# cslr_edmatc1_001 register map
Vendor: Texas Instruments
Peripheral module from a debugger description file.
Registers are 32-bit, read-only, reset 0x0 unless marked. A register's access mark holds for its fields unless they carry their own. Offsets are as the file gives them; lines under a group give offsets from that group; [hi:lo] are bit positions; {n}, {i} and the like mark numbered series; 'fields as' and 'values as' point back to an identical list; <NAME> marks a mode.

## EDMATC1 — Enhanced DMA Transfer Controller.
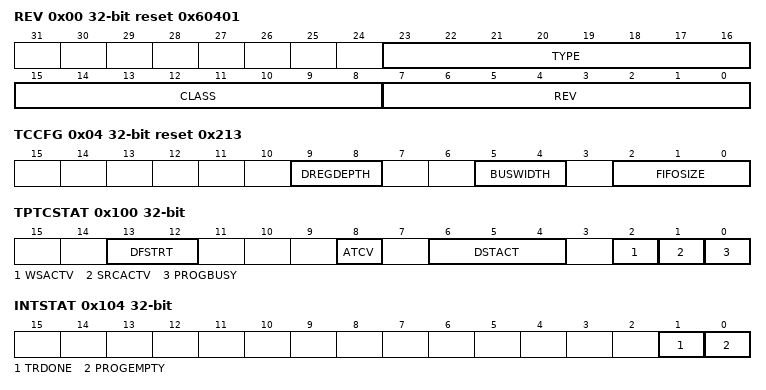
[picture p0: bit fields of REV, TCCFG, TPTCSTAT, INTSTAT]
0x00 REV reset 0x60401 — Peripheral Revision
  [23:16] TYPE — Peripheral Type
  [15:8] CLASS — Peripheral Class
  [7:0] REV — Revision
0x04 TCCFG reset 0x213 — TC Configuration
  [9:8] DREGDEPTH — Dst Register FIFO Depth Parametization
    2=4ENTRY
  [5:4] BUSWIDTH
    1=64BIT (64-bit (8 byte))
  [2:0] FIFOSIZE
    3=256BYTE (256 Byte Fifo)
0x100 TPTCSTAT — TPTC Status
  [13:12] DFSTRT — Dst FIFO Start Pointer
  [8] ATCV — Channel Active
    0=IDLE (Channel is Idle); 1=BUSY (Channel is busy)
  [6:4] DSTACT — Destination Active State
    0=EMPTY (Dst FIFO is empty); {v}={v}TR (Dst FIFO contains {v} TR) (v=1..4)
  [2] WSACTV — Write Status Active
    0=NONE (Write status is not pending); 1=PEND (Write Status is pending)
  [1] SRCACTV — Source Active State
    0=IDLE (Source Active set is idle and available for programming); 1=BUSY
  [0] PROGBUSY — Program Register Set Busy
    0=IDLE (Idle and available for programming); 1=BUSY
0x104 INTSTAT — Interrupt Status
  [1] TRDONE
    0=NONE (Condition not detected); 1=DONE (TC has complted a Transfer Request)
  [0] PROGEMPTY — Program Set Empty
    0=NONE (Condition not detected); 1=EMPTY (Program register set transitions to empty)
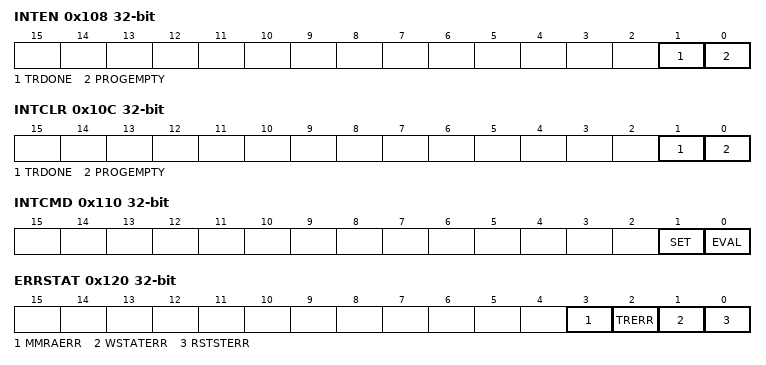
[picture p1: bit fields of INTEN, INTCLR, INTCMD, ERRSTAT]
0x108 INTEN access per field — Interrupt Enable
  [1] TRDONE rw
    0=DISABLE (Condition disabled); 1=ENABLE (Condition enabled)
  [0] PROGEMPTY rw — Program Set Empty
    0=DISABLE (Condition disabled); 1=ENABLE (Condition enabled)
0x10C INTCLR access per field — Interrupt Clear
  [1] TRDONE wo
    1=CLEAR (TR Interrupt cleared)
  [0] PROGEMPTY wo — Program Set Empty
    1=CLEAR (Program Empty Interrupt cleared)
0x110 INTCMD access per field — Interrupt Command
  [1] SET wo — Set tptc_int
    1=SET (Causes tptc_int to be pulsed unconditionally)
  [0] EVAL wo — Evaluate state of tptc_int output
    1=EVAL (Causes tptc_int to be pulsed is any of the INSTAT bits are '1'.)
0x120 ERRSTAT — Error Status
  [3] MMRAERR — MMR Address Error Event
    0=NONE (No error detected); 1=ERROR (User attempted to read/write invalid address)
  [2] TRERR — TR Error Event
    0=NONE (Condition not detected); 1=ERROR (FIFO Mode transfer violation)
  [1] WSTATERR — WSTAT Error Event
    0=NONE (Condition not detected); 1=ERROR (TC has detected an error code on the write response)
  [0] RSTSTERR — Rstate Error Event
    0=NONE (Condition not detected); 1=ERROR (TC has detected an error code on the read response)
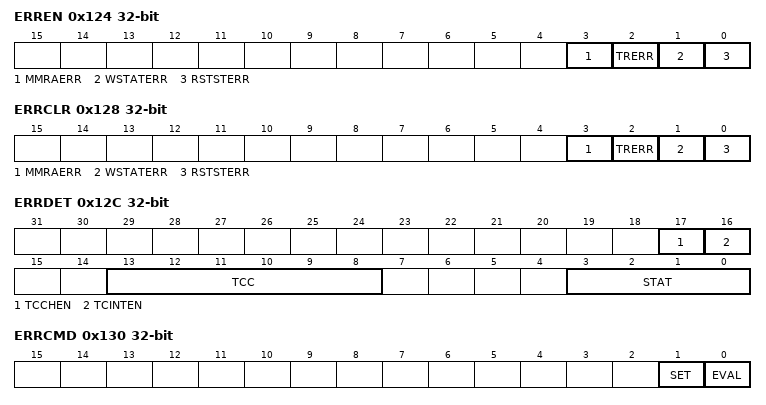
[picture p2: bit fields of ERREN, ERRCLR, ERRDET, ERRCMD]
0x124 ERREN — Error Enable
  [all] fields
    0=DISABLE (Error Source Disabled); 1=ENABLE (Error Source Enabled)
  [3] MMRAERR — MMR Address Error Event
  [2] TRERR — TR Error Event
  [1] WSTATERR — WSTAT Error Event
  [0] RSTSTERR — Rstate Error Event
0x128 ERRCLR — Error Clear Register
  [all] fields
    1=CLEAR (Error Cleared)
  [3] MMRAERR — MMR Address Error
  [2] TRERR — TR Error Event
  [1] WSTATERR — WSTAT Error Event
  [0] RSTSTERR — Rstate Error Event
0x12C ERRDET — Error Details
  [17] TCCHEN — Transfer Completion Chaining Enable
  [16] TCINTEN — Transfer Completion Interrupt Enable
  [13:8] TCC — Transfer Completion Code
  [3:0] STAT — Transation Status
    0=NONE (No Error); 1=READ_ADDRESS (Read Addressing Error); 2=READ_PRIVILEGE (Read Privilege Error); 3=READ_TIMEOUT (Read Timeout Error); 4=READ_DATA (Read Data Error); 7=READ_EXCLUSIVE (Read Exclusive operation Error); 9=WRITE_ADDRESS (Write Addressing Error); 10=WRITE_PRIVILEGE (Write Privilege Error); 11=WRITE_TIMEOUT (Write Timeout Error); 12=WRITE_DATA (Write Data Error); 15=WRITE_EXCLUSIVE (Write Exclusive operation Error)
0x130 ERRCMD access per field — Error Command
  [1] SET wo — Set tptc_errint output
    1=SET (Write of '1' causes tptc_errint to be pulsed unconditionally)
  [0] EVAL wo — Transfer Completion Interrupt Enable
    1=EVAL (Write of '1' causes tptc_errint to be pulsed if any of the ERRSTAT bits are set to '1')
0x140 RDRATE access per field — Read Command rate
  [2:0] RDRATE rw — Read rate
    0=AFAP (As Fast as possible); 1=4CYCLE (4 cycles between reads); 2=8CYCLE (8 cycles between reads); 3=16CYCLE (16 cycles between reads); 4=32CYCLE (32 cycles between reads)
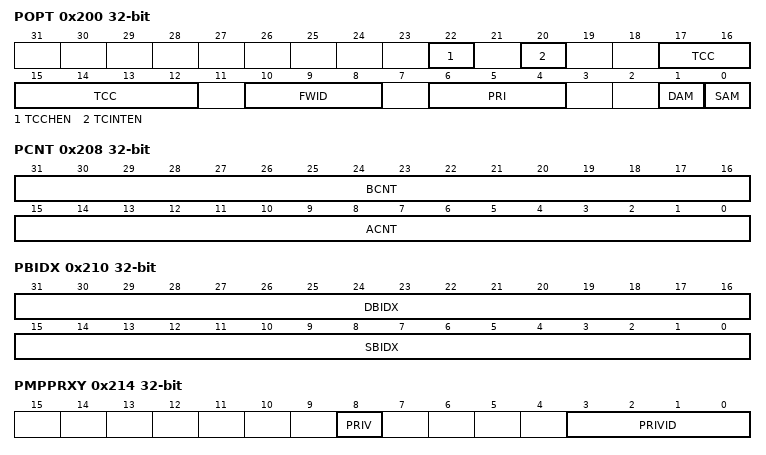
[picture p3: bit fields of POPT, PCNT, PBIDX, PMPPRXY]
0x200 POPT access per field — Prog Set Options
  [22] TCCHEN rw — Transfer Complete chaining enable
    0=DISABLE (Transfer complete chaning disable); 1=ENABLE (Transfer complete chaning enable)
  [20] TCINTEN rw — Transfer Complete interrupt enable
    0=DISABLE (Transfer complete interrupt disable); 1=ENABLE (Transfer complete interrupt enable)
  [17:12] TCC rw — Transfer Complete Code
  [10:8] FWID rw — Fifo Width
    0=8BIT (Fifo Width is 8-bit); 1=16BIT (Fifo Width is 16-bit); 2=32BIT (Fifo Width is 32-bit); 3=64BIT (Fifo Width is 64-bit); 4=128BIT (Fifo Width is 128-bit); 5=256BIT (Fifo Width is 256-bit)
  [6:4] PRI rw — Transfer Priority
  [1] DAM rw — Destination address mode within array
    0=INCR (Dst addressing within array increments); 1=FIFO (Dst addressing within array wraps around upon reaching FIFO width)
  [0] SAM ro — Source address mode within array
    0=INCR (Src addressing within array increments); 1=FIFO (Src addressing within array wraps around upon reaching FIFO width)
0x204 PSRC rw — Prog Set Src Address
  [31:0] SADDR — Source address for Program Register Set
0x208 PCNT rw — Prog Set Count
  [31:16] BCNT — B Dimension count
  [15:0] ACNT — A Dimension count
0x20C PDST rw — Prog Set Dst address
  [31:0] DADDR — Dst Address
0x210 PBIDX rw — Prog Set B-Dim Idx
  [31:16] DBIDX — B-Idx offset between Destination arrays
  [15:0] SBIDX — B-Idx offset between Source arrays
0x214 PMPPRXY — Prog Set Mem Protect Proxy
  [8] PRIV — Privilege Level
    0=USER (User level privilege); 1=SUPERVISOR (Supervisor level privilege)
  [3:0] PRIVID — Privilege ID
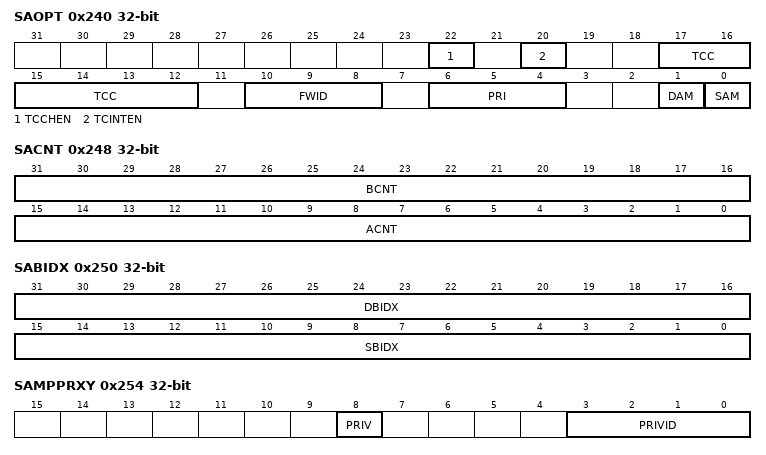
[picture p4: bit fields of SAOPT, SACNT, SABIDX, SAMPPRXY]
0x240 SAOPT — Src Actv Set Options
  [22] TCCHEN — Transfer Complete chaining enable
    values as POPT.TCCHEN
  [20] TCINTEN — Transfer Complete interrupt enable
    values as POPT.TCINTEN
  [17:12] TCC — Transfer Complete Code
  [10:8] FWID — Fifo Width
    values as POPT.FWID
  [6:4] PRI — Transfer Priority
  [1] DAM — Destination address mode within array
    values as POPT.DAM
  [0] SAM — Source address mode within array
    values as POPT.SAM
0x244 SASRC — Src Actv Set Src Address
  [31:0] SADDR — Source address for Program Register Set
0x248 SACNT — Src Actv Set Count
  [31:16] BCNT — B Dimension count
  [15:0] ACNT — A Dimension count
0x24C SADST — Src Actv Dst address
0x250 SABIDX rw — Src Actv Set B-Dim Idx
  fields as PBIDX
0x254 SAMPPRXY — Src Actv Set Mem Protect Proxy
  fields as PMPPRXY
0x258 SACNTRLD — Src Actv Set Cnt Reload
  [15:0] ACNTRLD — A-cnt Reload value
0x25C SASRCBREF — Src Actv Set Src Address B-reference
  [31:0] SADDRBREFG — Source address B-Reference
0x260 SADSTBREF — Src Actv Set Dst Address B-reference
0x280 DFCNTRLD — Dst FIFO Set Cnt Reload
  [15:0] ACNTRLD — A-Cnt Reload value
0x284 DFSRCBREF — Dst FIFO Set Dst Addr B Reference
0x288 DFDSTBREF — Dst FIFO Set Dst Addr B Reference
  [31:0] DADDRBREF — Destination address reference for Dst FIFO Register Set
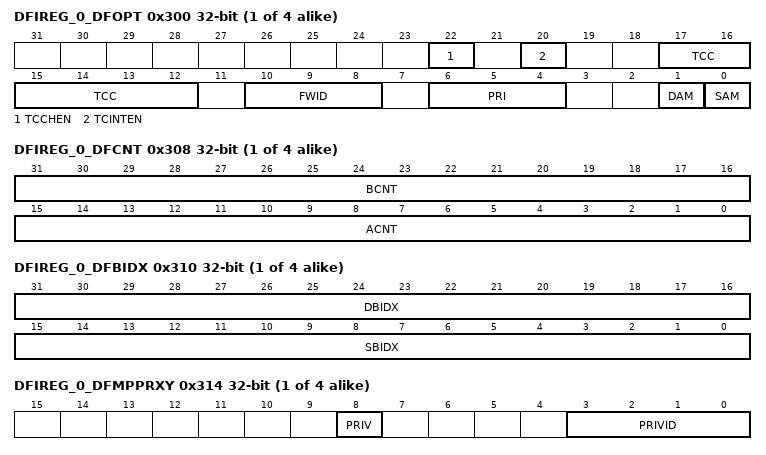
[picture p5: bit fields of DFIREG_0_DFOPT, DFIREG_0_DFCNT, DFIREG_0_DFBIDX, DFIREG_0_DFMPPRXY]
{0x300+0x40*i} DFIREG_{i}_DFOPT (i=0..3) — Dst FIFO Set Option
  fields as SAOPT
{0x304+0x40*i} DFIREG_{i}_DFSRC (i=0..3) — Dst Fifo Source address
{0x308+0x40*i} DFIREG_{i}_DFCNT (i=0..3) — Dst Fifo Set Count
  [31:16] BCNT — B Dimension count
  [15:0] ACNT — A Dimension count
{0x30C+0x40*i} DFIREG_{i}_DFDST (i=0..3) — Dst Fifo Set Dst Count
  [31:0] DADDR — Dst Address
{0x310+0x40*i} DFIREG_{i}_DFBIDX (i=0..3) — Dst Fifo Set B-Dim Idx
  fields as PBIDX
{0x314+0x40*i} DFIREG_{i}_DFMPPRXY (i=0..3) — Dst Fifo mem Protect Proxy
  fields as PMPPRXY
